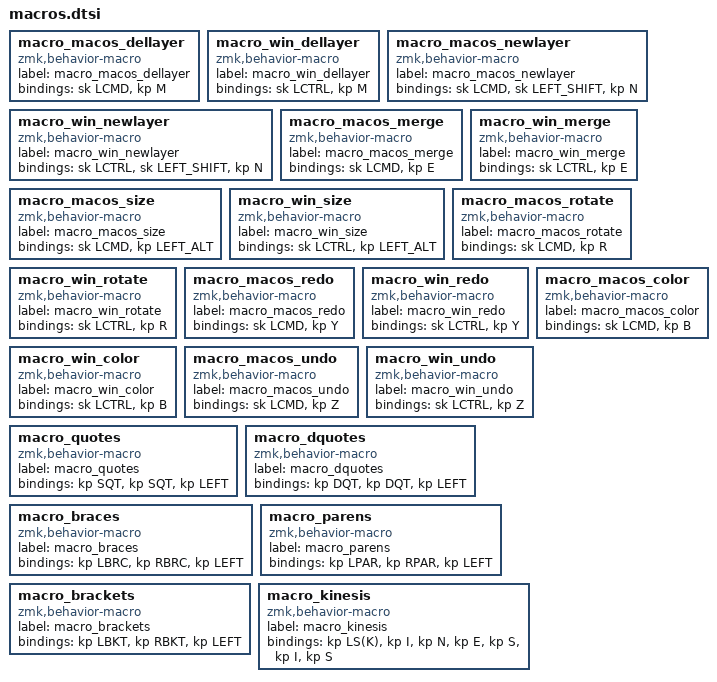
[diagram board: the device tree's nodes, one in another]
macro_macos_dellayer: macro_macos_dellayer{
compatible = "zmk,behavior-macro";
label = "macro_macos_dellayer";
#binding-cells = <0>;
bindings = <&sk LCMD>, <&kp M>;
};
macro_win_dellayer: macro_win_dellayer{
compatible = "zmk,behavior-macro";
label = "macro_win_dellayer";
#binding-cells = <0>;
bindings = <&sk LCTRL>, <&kp M>;
};
macro_macos_newlayer: macro_macos_newlayer{
compatible = "zmk,behavior-macro";
label = "macro_macos_newlayer";
#binding-cells = <0>;
bindings = <&sk LCMD>, <&sk LEFT_SHIFT>, <&kp N>;
};
macro_win_newlayer: macro_win_newlayer{
compatible = "zmk,behavior-macro";
label = "macro_win_newlayer";
#binding-cells = <0>;
bindings = <&sk LCTRL>, <&sk LEFT_SHIFT>, <&kp N>;
};
macro_macos_merge: macro_macos_merge{
compatible = "zmk,behavior-macro";
label = "macro_macos_merge";
#binding-cells = <0>;
bindings = <&sk LCMD>, <&kp E>;
};
macro_win_merge: macro_win_merge{
compatible = "zmk,behavior-macro";
label = "macro_win_merge";
#binding-cells = <0>;
bindings = <&sk LCTRL>, <&kp E>;
};
macro_macos_size: macro_macos_size{
compatible = "zmk,behavior-macro";
label = "macro_macos_size";
#binding-cells = <0>;
bindings = <&sk LCMD>, <&kp LEFT_ALT>;
};
macro_win_size: macro_win_size{
compatible = "zmk,behavior-macro";
label = "macro_win_size";
#binding-cells = <0>;
bindings = <&sk LCTRL>, <&kp LEFT_ALT>;
};
macro_macos_rotate: macro_macos_rotate{
compatible = "zmk,behavior-macro";
label = "macro_macos_rotate";
#binding-cells = <0>;
bindings = <&sk LCMD>, <&kp R>;
};
macro_win_rotate: macro_win_rotate{
compatible = "zmk,behavior-macro";
label = "macro_win_rotate";
#binding-cells = <0>;
bindings = <&sk LCTRL>, <&kp R>;
};
macro_macos_redo: macro_macos_redo{
compatible = "zmk,behavior-macro";
label = "macro_macos_redo";
#binding-cells = <0>;
bindings = <&sk LCMD>, <&kp Y>;
};
macro_win_redo: macro_win_redo{
compatible = "zmk,behavior-macro";
label = "macro_win_redo";
#binding-cells = <0>;
bindings = <&sk LCTRL>, <&kp Y>;
};
macro_macos_color: macro_macos_color{
compatible = "zmk,behavior-macro";
label = "macro_macos_color";
#binding-cells = <0>;
bindings = <&sk LCMD>, <&kp B>;
};
macro_win_color: macro_win_color{
compatible = "zmk,behavior-macro";
label = "macro_win_color";
#binding-cells = <0>;
bindings = <&sk LCTRL>, <&kp B>;
};
macro_macos_undo: macro_macos_undo{
compatible = "zmk,behavior-macro";
label = "macro_macos_undo";
#binding-cells = <0>;
bindings = <&sk LCMD>, <&kp Z>;
};
macro_win_undo: macro_win_undo{
compatible = "zmk,behavior-macro";
label = "macro_win_undo";
#binding-cells = <0>;
bindings = <&sk LCTRL>, <&kp Z>;
};
macro_quotes: macro_quotes{
compatible = "zmk,behavior-macro";
label = "macro_quotes";
#binding-cells = <0>;
bindings = <&kp SQT>, <&kp SQT>, <&kp LEFT>;
};
macro_dquotes: macro_dquotes{
compatible = "zmk,behavior-macro";
label = "macro_dquotes";
#binding-cells = <0>;
bindings = <&kp DQT>, <&kp DQT>, <&kp LEFT>;
};
macro_braces: macro_braces{
compatible = "zmk,behavior-macro";
label = "macro_braces";
#binding-cells = <0>;
bindings = <&kp LBRC>, <&kp RBRC>, <&kp LEFT>;
};
macro_parens: macro_parens{
compatible = "zmk,behavior-macro";
label = "macro_parens";
#binding-cells = <0>;
bindings = <&kp LPAR>, <&kp RPAR>, <&kp LEFT>;
};
macro_brackets: macro_brackets{
compatible = "zmk,behavior-macro";
label = "macro_brackets";
#binding-cells = <0>;
bindings = <&kp LBKT>, <&kp RBKT>, <&kp LEFT>;
};
macro_kinesis: macro_kinesis{
compatible = "zmk,behavior-macro";
label = "macro_kinesis";
#binding-cells = <0>;
bindings = <&kp LS(K)>, <&kp I>, <&kp N>, <&kp E>, <&kp S>, <&kp I>, <&kp S>;
};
